# STM32L4Q5ZGT6P register map
File version: 1.0
Registers are 32-bit, access not given, reset 0x0 unless marked. A register's access mark holds for its fields unless they carry their own. Offsets are from the block's base; [hi:lo] are bit positions.

## PKA
Base 0x5005E000
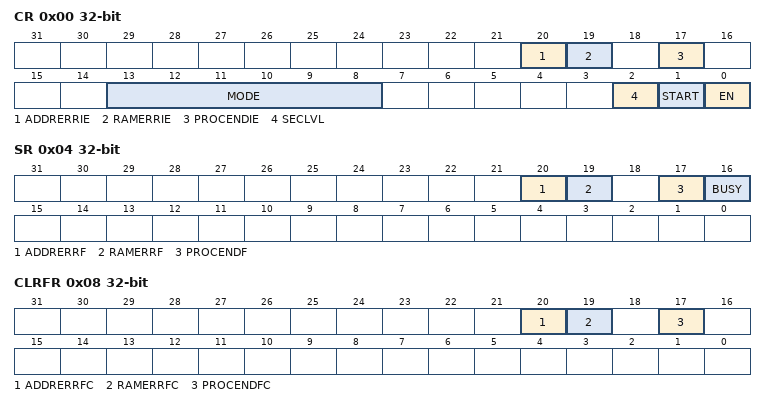
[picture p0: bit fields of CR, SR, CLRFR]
0x00 CR
  [20] ADDRERRIE, [19] RAMERRIE, [17] PROCENDIE, [13:8] MODE, [2] SECLVL, [1] START, [0] EN
0x04 SR
  [20] ADDRERRF, [19] RAMERRF, [17] PROCENDF, [16] BUSY
0x08 CLRFR
  [20] ADDRERRFC, [19] RAMERRFC, [17] PROCENDFC
0x400 RAM.0
0x404 RAM.1
0x408 RAM.2
0x40C RAM.3
0x410 RAM.4
0x414 RAM.5
0x418 RAM.6
0x41C RAM.7
0x420 RAM.8
0x424 RAM.9
0x428 RAM.10
0x42C RAM.11
0x430 RAM.12
0x434 RAM.13
0x438 RAM.14
0x43C RAM.15
0x440 RAM.16
0x444 RAM.17
0x448 RAM.18
0x44C RAM.19
0x450 RAM.20
0x454 RAM.21
0x458 RAM.22
0x45C RAM.23
0x460 RAM.24
0x464 RAM.25
0x468 RAM.26
0x46C RAM.27
0x470 RAM.28
0x474 RAM.29
0x478 RAM.30
0x47C RAM.31
0x480 RAM.32
0x484 RAM.33
0x488 RAM.34
0x48C RAM.35
0x490 RAM.36
0x494 RAM.37
0x498 RAM.38
0x49C RAM.39
0x4A0 RAM.40
0x4A4 RAM.41
0x4A8 RAM.42
0x4AC RAM.43
0x4B0 RAM.44
0x4B4 RAM.45
0x4B8 RAM.46
0x4BC RAM.47
0x4C0 RAM.48
0x4C4 RAM.49
0x4C8 RAM.50
0x4CC RAM.51
0x4D0 RAM.52
0x4D4 RAM.53
0x4D8 RAM.54
0x4DC RAM.55
0x4E0 RAM.56
0x4E4 RAM.57
0x4E8 RAM.58
0x4EC RAM.59
0x4F0 RAM.60
0x4F4 RAM.61
0x4F8 RAM.62
0x4FC RAM.63
0x500 RAM.64
0x504 RAM.65
0x508 RAM.66
0x50C RAM.67
0x510 RAM.68
0x514 RAM.69
0x518 RAM.70
0x51C RAM.71
0x520 RAM.72
0x524 RAM.73
0x528 RAM.74
0x52C RAM.75
0x530 RAM.76
0x534 RAM.77
0x538 RAM.78
0x53C RAM.79
0x540 RAM.80
0x544 RAM.81
0x548 RAM.82
0x54C RAM.83
0x550 RAM.84
0x554 RAM.85
0x558 RAM.86
0x55C RAM.87
0x560 RAM.88
0x564 RAM.89
0x568 RAM.90
0x56C RAM.91
0x570 RAM.92
0x574 RAM.93
0x578 RAM.94
0x57C RAM.95
0x580 RAM.96
0x584 RAM.97
0x588 RAM.98
0x58C RAM.99
0x590 RAM.100
0x594 RAM.101
0x598 RAM.102
0x59C RAM.103
0x5A0 RAM.104
0x5A4 RAM.105
0x5A8 RAM.106
0x5AC RAM.107
0x5B0 RAM.108
0x5B4 RAM.109
0x5B8 RAM.110
0x5BC RAM.111
0x5C0 RAM.112
0x5C4 RAM.113
0x5C8 RAM.114
0x5CC RAM.115
0x5D0 RAM.116
0x5D4 RAM.117
0x5D8 RAM.118
0x5DC RAM.119
0x5E0 RAM.120
0x5E4 RAM.121
0x5E8 RAM.122
0x5EC RAM.123
0x5F0 RAM.124
0x5F4 RAM.125
0x5F8 RAM.126
0x5FC RAM.127
0x600 RAM.128
0x604 RAM.129
0x608 RAM.130
0x60C RAM.131
0x610 RAM.132
0x614 RAM.133
0x618 RAM.134
0x61C RAM.135
0x620 RAM.136
0x624 RAM.137
0x628 RAM.138
0x62C RAM.139
0x630 RAM.140
0x634 RAM.141
0x638 RAM.142
0x63C RAM.143
0x640 RAM.144
0x644 RAM.145
0x648 RAM.146
0x64C RAM.147
0x650 RAM.148
0x654 RAM.149
0x658 RAM.150
0x65C RAM.151
0x660 RAM.152
0x664 RAM.153
0x668 RAM.154
0x66C RAM.155
0x670 RAM.156
0x674 RAM.157
0x678 RAM.158
0x67C RAM.159
0x680 RAM.160
0x684 RAM.161
0x688 RAM.162
0x68C RAM.163
0x690 RAM.164
0x694 RAM.165
0x698 RAM.166
0x69C RAM.167
0x6A0 RAM.168
0x6A4 RAM.169
0x6A8 RAM.170
0x6AC RAM.171
0x6B0 RAM.172
0x6B4 RAM.173
0x6B8 RAM.174
0x6BC RAM.175
0x6C0 RAM.176
0x6C4 RAM.177
0x6C8 RAM.178
0x6CC RAM.179
0x6D0 RAM.180
0x6D4 RAM.181
0x6D8 RAM.182
0x6DC RAM.183
0x6E0 RAM.184
0x6E4 RAM.185
0x6E8 RAM.186
0x6EC RAM.187
0x6F0 RAM.188
0x6F4 RAM.189
0x6F8 RAM.190
0x6FC RAM.191
0x700 RAM.192
0x704 RAM.193
0x708 RAM.194
0x70C RAM.195
0x710 RAM.196
0x714 RAM.197
0x718 RAM.198
0x71C RAM.199
0x720 RAM.200
0x724 RAM.201
0x728 RAM.202
0x72C RAM.203
0x730 RAM.204
0x734 RAM.205
0x738 RAM.206
0x73C RAM.207
0x740 RAM.208
0x744 RAM.209
0x748 RAM.210
0x74C RAM.211
0x750 RAM.212
0x754 RAM.213
0x758 RAM.214
0x75C RAM.215
0x760 RAM.216
0x764 RAM.217
0x768 RAM.218
0x76C RAM.219
0x770 RAM.220
0x774 RAM.221
0x778 RAM.222
0x77C RAM.223
0x780 RAM.224
0x784 RAM.225
0x788 RAM.226
0x78C RAM.227
0x790 RAM.228
0x794 RAM.229
0x798 RAM.230
0x79C RAM.231
0x7A0 RAM.232
0x7A4 RAM.233
0x7A8 RAM.234
0x7AC RAM.235
0x7B0 RAM.236
0x7B4 RAM.237
0x7B8 RAM.238
0x7BC RAM.239
0x7C0 RAM.240
0x7C4 RAM.241
0x7C8 RAM.242
0x7CC RAM.243
0x7D0 RAM.244
0x7D4 RAM.245
0x7D8 RAM.246
0x7DC RAM.247
0x7E0 RAM.248
0x7E4 RAM.249
0x7E8 RAM.250
0x7EC RAM.251
0x7F0 RAM.252
0x7F4 RAM.253
0x7F8 RAM.254
0x7FC RAM.255
0x800 RAM.256
0x804 RAM.257
0x808 RAM.258
0x80C RAM.259
0x810 RAM.260
0x814 RAM.261
0x818 RAM.262
0x81C RAM.263
0x820 RAM.264
0x824 RAM.265
0x828 RAM.266
0x82C RAM.267
0x830 RAM.268
0x834 RAM.269
0x838 RAM.270
0x83C RAM.271
0x840 RAM.272
0x844 RAM.273
0x848 RAM.274
0x84C RAM.275
0x850 RAM.276
0x854 RAM.277
0x858 RAM.278
0x85C RAM.279
0x860 RAM.280
0x864 RAM.281
0x868 RAM.282
0x86C RAM.283
0x870 RAM.284
0x874 RAM.285
0x878 RAM.286
0x87C RAM.287
0x880 RAM.288
0x884 RAM.289
0x888 RAM.290
0x88C RAM.291
0x890 RAM.292
0x894 RAM.293
0x898 RAM.294
0x89C RAM.295
0x8A0 RAM.296
0x8A4 RAM.297
0x8A8 RAM.298
0x8AC RAM.299
0x8B0 RAM.300
0x8B4 RAM.301
0x8B8 RAM.302
0x8BC RAM.303
0x8C0 RAM.304
0x8C4 RAM.305
0x8C8 RAM.306
0x8CC RAM.307
0x8D0 RAM.308
0x8D4 RAM.309
0x8D8 RAM.310
0x8DC RAM.311
0x8E0 RAM.312
0x8E4 RAM.313
0x8E8 RAM.314
0x8EC RAM.315
0x8F0 RAM.316
0x8F4 RAM.317
0x8F8 RAM.318
0x8FC RAM.319
0x900 RAM.320
0x904 RAM.321
0x908 RAM.322
0x90C RAM.323
0x910 RAM.324
0x914 RAM.325
0x918 RAM.326
0x91C RAM.327
0x920 RAM.328
0x924 RAM.329
0x928 RAM.330
0x92C RAM.331
0x930 RAM.332
0x934 RAM.333
0x938 RAM.334
0x93C RAM.335
0x940 RAM.336
0x944 RAM.337
0x948 RAM.338
0x94C RAM.339
0x950 RAM.340
0x954 RAM.341
0x958 RAM.342
0x95C RAM.343
0x960 RAM.344
0x964 RAM.345
0x968 RAM.346
0x96C RAM.347
0x970 RAM.348
0x974 RAM.349
0x978 RAM.350
0x97C RAM.351
0x980 RAM.352
0x984 RAM.353
0x988 RAM.354
0x98C RAM.355
0x990 RAM.356
0x994 RAM.357
0x998 RAM.358
0x99C RAM.359
0x9A0 RAM.360
0x9A4 RAM.361
0x9A8 RAM.362
0x9AC RAM.363
0x9B0 RAM.364
0x9B4 RAM.365
0x9B8 RAM.366
0x9BC RAM.367
0x9C0 RAM.368
0x9C4 RAM.369
0x9C8 RAM.370
0x9CC RAM.371
0x9D0 RAM.372
0x9D4 RAM.373
0x9D8 RAM.374
0x9DC RAM.375
0x9E0 RAM.376
0x9E4 RAM.377
0x9E8 RAM.378
0x9EC RAM.379
0x9F0 RAM.380
0x9F4 RAM.381
0x9F8 RAM.382
0x9FC RAM.383
0xA00 RAM.384
0xA04 RAM.385
0xA08 RAM.386
0xA0C RAM.387
0xA10 RAM.388
0xA14 RAM.389
0xA18 RAM.390
0xA1C RAM.391
0xA20 RAM.392
0xA24 RAM.393
0xA28 RAM.394
0xA2C RAM.395
0xA30 RAM.396
0xA34 RAM.397
0xA38 RAM.398
0xA3C RAM.399
0xA40 RAM.400
0xA44 RAM.401
0xA48 RAM.402
0xA4C RAM.403
0xA50 RAM.404
0xA54 RAM.405
0xA58 RAM.406
0xA5C RAM.407
0xA60 RAM.408
0xA64 RAM.409
0xA68 RAM.410
0xA6C RAM.411
0xA70 RAM.412
0xA74 RAM.413
0xA78 RAM.414
0xA7C RAM.415
0xA80 RAM.416
0xA84 RAM.417
0xA88 RAM.418
0xA8C RAM.419
0xA90 RAM.420
0xA94 RAM.421
0xA98 RAM.422
0xA9C RAM.423
0xAA0 RAM.424
0xAA4 RAM.425
0xAA8 RAM.426
0xAAC RAM.427
0xAB0 RAM.428
0xAB4 RAM.429
0xAB8 RAM.430
0xABC RAM.431
0xAC0 RAM.432
0xAC4 RAM.433
0xAC8 RAM.434
0xACC RAM.435
0xAD0 RAM.436
0xAD4 RAM.437
0xAD8 RAM.438
0xADC RAM.439
0xAE0 RAM.440
0xAE4 RAM.441
0xAE8 RAM.442
0xAEC RAM.443
0xAF0 RAM.444
0xAF4 RAM.445
0xAF8 RAM.446
0xAFC RAM.447
0xB00 RAM.448
0xB04 RAM.449
0xB08 RAM.450
0xB0C RAM.451
0xB10 RAM.452
0xB14 RAM.453
0xB18 RAM.454
0xB1C RAM.455
0xB20 RAM.456
0xB24 RAM.457
0xB28 RAM.458
0xB2C RAM.459
0xB30 RAM.460
0xB34 RAM.461
0xB38 RAM.462
0xB3C RAM.463
0xB40 RAM.464
0xB44 RAM.465
0xB48 RAM.466
0xB4C RAM.467
0xB50 RAM.468
0xB54 RAM.469
0xB58 RAM.470
0xB5C RAM.471
0xB60 RAM.472
0xB64 RAM.473
0xB68 RAM.474
0xB6C RAM.475
0xB70 RAM.476
0xB74 RAM.477
0xB78 RAM.478
0xB7C RAM.479
0xB80 RAM.480
0xB84 RAM.481
0xB88 RAM.482
0xB8C RAM.483
0xB90 RAM.484
0xB94 RAM.485
0xB98 RAM.486
0xB9C RAM.487
0xBA0 RAM.488
0xBA4 RAM.489
0xBA8 RAM.490
0xBAC RAM.491
0xBB0 RAM.492
0xBB4 RAM.493
0xBB8 RAM.494
0xBBC RAM.495
0xBC0 RAM.496
0xBC4 RAM.497
0xBC8 RAM.498
0xBCC RAM.499
0xBD0 RAM.500
0xBD4 RAM.501
0xBD8 RAM.502
0xBDC RAM.503
0xBE0 RAM.504
0xBE4 RAM.505
0xBE8 RAM.506
0xBEC RAM.507
0xBF0 RAM.508
0xBF4 RAM.509
0xBF8 RAM.510
0xBFC RAM.511
0xC00 RAM.512
0xC04 RAM.513
0xC08 RAM.514
0xC0C RAM.515
0xC10 RAM.516
0xC14 RAM.517
0xC18 RAM.518
0xC1C RAM.519
0xC20 RAM.520
0xC24 RAM.521
0xC28 RAM.522
0xC2C RAM.523
0xC30 RAM.524
0xC34 RAM.525
0xC38 RAM.526
0xC3C RAM.527
0xC40 RAM.528
0xC44 RAM.529
0xC48 RAM.530
0xC4C RAM.531
0xC50 RAM.532
0xC54 RAM.533
0xC58 RAM.534
0xC5C RAM.535
0xC60 RAM.536
0xC64 RAM.537
0xC68 RAM.538
0xC6C RAM.539
0xC70 RAM.540
0xC74 RAM.541
0xC78 RAM.542
0xC7C RAM.543
0xC80 RAM.544
0xC84 RAM.545
0xC88 RAM.546
0xC8C RAM.547
0xC90 RAM.548
0xC94 RAM.549
0xC98 RAM.550
0xC9C RAM.551
0xCA0 RAM.552
0xCA4 RAM.553
0xCA8 RAM.554
0xCAC RAM.555
0xCB0 RAM.556
0xCB4 RAM.557
0xCB8 RAM.558
0xCBC RAM.559
0xCC0 RAM.560
0xCC4 RAM.561
0xCC8 RAM.562
0xCCC RAM.563
0xCD0 RAM.564
0xCD4 RAM.565
0xCD8 RAM.566
0xCDC RAM.567
0xCE0 RAM.568
0xCE4 RAM.569
0xCE8 RAM.570
0xCEC RAM.571
0xCF0 RAM.572
0xCF4 RAM.573
0xCF8 RAM.574
0xCFC RAM.575
0xD00 RAM.576
0xD04 RAM.577
0xD08 RAM.578
0xD0C RAM.579
0xD10 RAM.580
0xD14 RAM.581
0xD18 RAM.582
0xD1C RAM.583
0xD20 RAM.584
0xD24 RAM.585
0xD28 RAM.586
0xD2C RAM.587
0xD30 RAM.588
0xD34 RAM.589
0xD38 RAM.590
0xD3C RAM.591
0xD40 RAM.592
0xD44 RAM.593
0xD48 RAM.594
0xD4C RAM.595
0xD50 RAM.596
0xD54 RAM.597
0xD58 RAM.598
0xD5C RAM.599
0xD60 RAM.600
0xD64 RAM.601
0xD68 RAM.602
0xD6C RAM.603
0xD70 RAM.604
0xD74 RAM.605
0xD78 RAM.606
0xD7C RAM.607
0xD80 RAM.608
0xD84 RAM.609
0xD88 RAM.610
0xD8C RAM.611
0xD90 RAM.612
0xD94 RAM.613
0xD98 RAM.614
0xD9C RAM.615
0xDA0 RAM.616
0xDA4 RAM.617
0xDA8 RAM.618
0xDAC RAM.619
0xDB0 RAM.620
0xDB4 RAM.621
0xDB8 RAM.622
0xDBC RAM.623
0xDC0 RAM.624
0xDC4 RAM.625
0xDC8 RAM.626
0xDCC RAM.627
0xDD0 RAM.628
0xDD4 RAM.629
0xDD8 RAM.630
0xDDC RAM.631
0xDE0 RAM.632
0xDE4 RAM.633
0xDE8 RAM.634
0xDEC RAM.635
0xDF0 RAM.636
0xDF4 RAM.637
0xDF8 RAM.638
0xDFC RAM.639
0xE00 RAM.640
0xE04 RAM.641
0xE08 RAM.642
0xE0C RAM.643
0xE10 RAM.644
0xE14 RAM.645
0xE18 RAM.646
0xE1C RAM.647
0xE20 RAM.648
0xE24 RAM.649
0xE28 RAM.650
0xE2C RAM.651
0xE30 RAM.652
0xE34 RAM.653
0xE38 RAM.654
0xE3C RAM.655
0xE40 RAM.656
0xE44 RAM.657
0xE48 RAM.658
0xE4C RAM.659
0xE50 RAM.660
0xE54 RAM.661
0xE58 RAM.662
0xE5C RAM.663
0xE60 RAM.664
0xE64 RAM.665
0xE68 RAM.666
0xE6C RAM.667
0xE70 RAM.668
0xE74 RAM.669
0xE78 RAM.670
0xE7C RAM.671
0xE80 RAM.672
0xE84 RAM.673
0xE88 RAM.674
0xE8C RAM.675
0xE90 RAM.676
0xE94 RAM.677
0xE98 RAM.678
0xE9C RAM.679
0xEA0 RAM.680
0xEA4 RAM.681
0xEA8 RAM.682
0xEAC RAM.683
0xEB0 RAM.684
0xEB4 RAM.685
0xEB8 RAM.686
0xEBC RAM.687
0xEC0 RAM.688
0xEC4 RAM.689
0xEC8 RAM.690
0xECC RAM.691
0xED0 RAM.692
0xED4 RAM.693
0xED8 RAM.694
0xEDC RAM.695
0xEE0 RAM.696
0xEE4 RAM.697
0xEE8 RAM.698
0xEEC RAM.699
0xEF0 RAM.700
0xEF4 RAM.701
0xEF8 RAM.702
0xEFC RAM.703
0xF00 RAM.704
0xF04 RAM.705
0xF08 RAM.706
0xF0C RAM.707
0xF10 RAM.708
0xF14 RAM.709
0xF18 RAM.710
0xF1C RAM.711
0xF20 RAM.712
0xF24 RAM.713
0xF28 RAM.714
0xF2C RAM.715
0xF30 RAM.716
0xF34 RAM.717
0xF38 RAM.718
0xF3C RAM.719
0xF40 RAM.720
0xF44 RAM.721
0xF48 RAM.722
0xF4C RAM.723
0xF50 RAM.724
0xF54 RAM.725
0xF58 RAM.726
0xF5C RAM.727
0xF60 RAM.728
0xF64 RAM.729
0xF68 RAM.730
0xF6C RAM.731
0xF70 RAM.732
0xF74 RAM.733
0xF78 RAM.734
0xF7C RAM.735
0xF80 RAM.736
0xF84 RAM.737
0xF88 RAM.738
0xF8C RAM.739
0xF90 RAM.740
0xF94 RAM.741
0xF98 RAM.742
0xF9C RAM.743
0xFA0 RAM.744
0xFA4 RAM.745
0xFA8 RAM.746
0xFAC RAM.747
0xFB0 RAM.748
0xFB4 RAM.749
0xFB8 RAM.750
0xFBC RAM.751
0xFC0 RAM.752
0xFC4 RAM.753
0xFC8 RAM.754
0xFCC RAM.755
0xFD0 RAM.756
0xFD4 RAM.757
0xFD8 RAM.758
0xFDC RAM.759
0xFE0 RAM.760
0xFE4 RAM.761
0xFE8 RAM.762
0xFEC RAM.763
0xFF0 RAM.764
0xFF4 RAM.765
0xFF8 RAM.766
0xFFC RAM.767
0x1000 RAM.768
0x1004 RAM.769
0x1008 RAM.770
0x100C RAM.771
0x1010 RAM.772
0x1014 RAM.773
0x1018 RAM.774
0x101C RAM.775
0x1020 RAM.776
0x1024 RAM.777
0x1028 RAM.778
0x102C RAM.779
0x1030 RAM.780
0x1034 RAM.781
0x1038 RAM.782
0x103C RAM.783
0x1040 RAM.784
0x1044 RAM.785
0x1048 RAM.786
0x104C RAM.787
0x1050 RAM.788
0x1054 RAM.789
0x1058 RAM.790
0x105C RAM.791
0x1060 RAM.792
0x1064 RAM.793
0x1068 RAM.794
0x106C RAM.795
0x1070 RAM.796
0x1074 RAM.797
0x1078 RAM.798
0x107C RAM.799
0x1080 RAM.800
0x1084 RAM.801
0x1088 RAM.802
0x108C RAM.803
0x1090 RAM.804
0x1094 RAM.805
0x1098 RAM.806
0x109C RAM.807
0x10A0 RAM.808
0x10A4 RAM.809
0x10A8 RAM.810
0x10AC RAM.811
0x10B0 RAM.812
0x10B4 RAM.813
0x10B8 RAM.814
0x10BC RAM.815
0x10C0 RAM.816
0x10C4 RAM.817
0x10C8 RAM.818
0x10CC RAM.819
0x10D0 RAM.820
0x10D4 RAM.821
0x10D8 RAM.822
0x10DC RAM.823
0x10E0 RAM.824
0x10E4 RAM.825
0x10E8 RAM.826
0x10EC RAM.827
0x10F0 RAM.828
0x10F4 RAM.829
0x10F8 RAM.830
0x10FC RAM.831
0x1100 RAM.832
0x1104 RAM.833
0x1108 RAM.834
0x110C RAM.835
0x1110 RAM.836
0x1114 RAM.837
0x1118 RAM.838
0x111C RAM.839
0x1120 RAM.840
0x1124 RAM.841
0x1128 RAM.842
0x112C RAM.843
0x1130 RAM.844
0x1134 RAM.845
0x1138 RAM.846
0x113C RAM.847
0x1140 RAM.848
0x1144 RAM.849
0x1148 RAM.850
0x114C RAM.851
0x1150 RAM.852
0x1154 RAM.853
0x1158 RAM.854
0x115C RAM.855
0x1160 RAM.856
0x1164 RAM.857
0x1168 RAM.858
0x116C RAM.859
0x1170 RAM.860
0x1174 RAM.861
0x1178 RAM.862
0x117C RAM.863
0x1180 RAM.864
0x1184 RAM.865
0x1188 RAM.866
0x118C RAM.867
0x1190 RAM.868
0x1194 RAM.869
0x1198 RAM.870
0x119C RAM.871
0x11A0 RAM.872
0x11A4 RAM.873
0x11A8 RAM.874
0x11AC RAM.875
0x11B0 RAM.876
0x11B4 RAM.877
0x11B8 RAM.878
0x11BC RAM.879
0x11C0 RAM.880
0x11C4 RAM.881
0x11C8 RAM.882
0x11CC RAM.883
0x11D0 RAM.884
0x11D4 RAM.885
0x11D8 RAM.886
0x11DC RAM.887
0x11E0 RAM.888
0x11E4 RAM.889
0x11E8 RAM.890
0x11EC RAM.891
0x11F0 RAM.892
0x11F4 RAM.893
